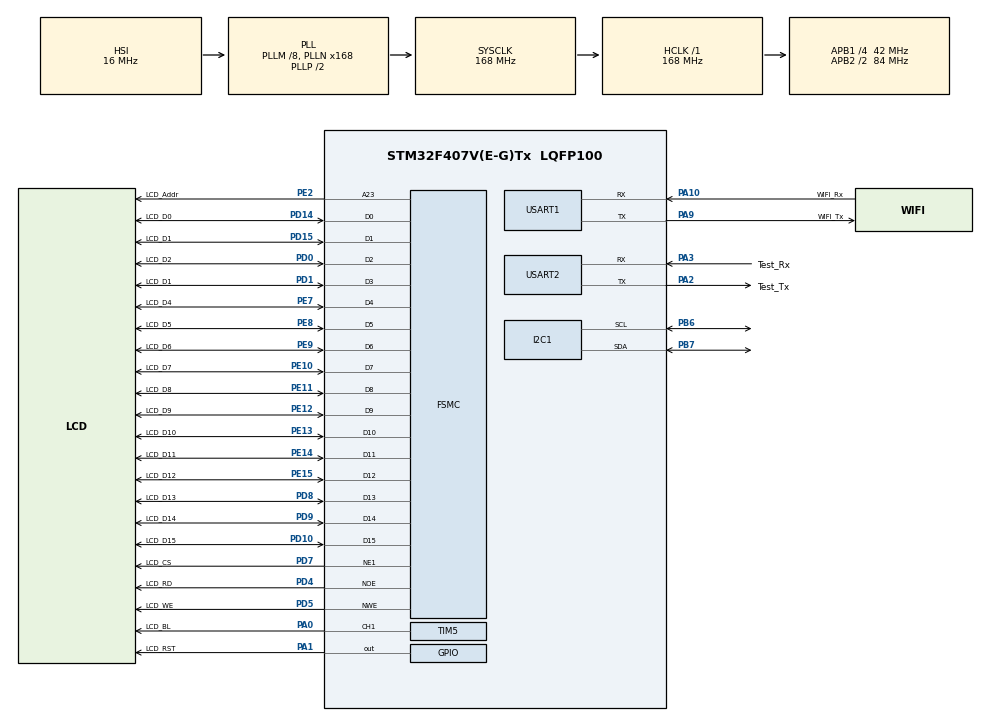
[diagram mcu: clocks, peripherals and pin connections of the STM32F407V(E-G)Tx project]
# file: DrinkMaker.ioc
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FREERTOS.Tasks01=defaultTask,24,128,StartDefaultTask,Default,NULL,Dynamic,NULL,NULL
FREERTOS.configTOTAL_HEAP_SIZE=30720
FSMC.AddressSetupTime1=3
FSMC.BusTurnAroundDuration1=0
FSMC.DataSetupTime1=40
FSMC.ExtendedAddressSetupTime1=0
FSMC.ExtendedDataSetupTime1=10
FSMC.ExtendedMode1=FSMC_EXTENDED_MODE_ENABLE
Mcu.Family=STM32F4
Mcu.Name=STM32F407V(E-G)Tx
Mcu.Package=LQFP100
NVIC.PriorityGroup=NVIC_PRIORITYGROUP_4
NVIC.TIM7_IRQn=true\:15\:0\:false\:false\:true\:false\:false\:true\:true
NVIC.TimeBase=TIM7_IRQn
NVIC.TimeBaseIP=TIM7
PA0-WKUP.GPIO_Label=LCD_BL
PA0-WKUP.GPIO_Speed=GPIO_SPEED_FREQ_VERY_HIGH
PA0-WKUP.Signal=S_TIM5_CH1
PA1.GPIO_Label=LCD_RST
PA1.GPIO_Speed=GPIO_SPEED_FREQ_HIGH
PA1.PinState=GPIO_PIN_SET
PA1.Signal=GPIO_Output
PA10.GPIO_Label=WIFI_Rx
PA10.Mode=Asynchronous
PA10.Signal=USART1_RX
PA2.GPIO_Label=Test_Tx
PA2.Mode=Asynchronous
PA2.Signal=USART2_TX
PA3.GPIO_Label=Test_Rx
PA3.Mode=Asynchronous
PA3.Signal=USART2_RX
PA9.GPIO_Label=WIFI_Tx
PA9.Mode=Asynchronous
PA9.Signal=USART1_TX
PB6.Mode=I2C
PB6.Signal=I2C1_SCL
PB7.Mode=I2C
PB7.Signal=I2C1_SDA
PC14-OSC32_IN.Mode=LSE-External-Oscillator
PC14-OSC32_IN.Signal=RCC_OSC32_IN
PC15-OSC32_OUT.Mode=LSE-External-Oscillator
PC15-OSC32_OUT.Signal=RCC_OSC32_OUT
PD0.GPIO_Label=LCD_D2
PD0.Mode=16b-d1
PD0.Signal=FSMC_D2
PD1.GPIO_Label=LCD_D1
PD1.Mode=16b-d1
PD1.Signal=FSMC_D3
PD10.GPIO_Label=LCD_D15
PD10.Mode=16b-d1
PD10.Signal=FSMC_D15
PD14.GPIO_Label=LCD_D0
PD14.Mode=16b-d1
PD14.Signal=FSMC_D0
PD15.GPIO_Label=LCD_D1
PD15.Mode=16b-d1
PD15.Signal=FSMC_D1
PD4.GPIO_Label=LCD_RD
PD4.Mode=Lcd1
PD4.Signal=FSMC_NOE
PD5.GPIO_Label=LCD_WE
PD5.Mode=Lcd1
PD5.Signal=FSMC_NWE
PD7.GPIO_Label=LCD_CS
PD7.Mode=NorPsramChipSelect1_1
PD7.Signal=FSMC_NE1
PD8.GPIO_Label=LCD_D13
PD8.Mode=16b-d1
PD8.Signal=FSMC_D13
PD9.GPIO_Label=LCD_D14
PD9.Mode=16b-d1
PD9.Signal=FSMC_D14
PE10.GPIO_Label=LCD_D7
PE10.Mode=16b-d1
PE10.Signal=FSMC_D7
PE11.GPIO_Label=LCD_D8
PE11.Mode=16b-d1
PE11.Signal=FSMC_D8
PE12.GPIO_Label=LCD_D9
PE12.Mode=16b-d1
PE12.Signal=FSMC_D9
PE13.GPIO_Label=LCD_D10
PE13.Mode=16b-d1
PE13.Signal=FSMC_D10
PE14.GPIO_Label=LCD_D11
PE14.Mode=16b-d1
PE14.Signal=FSMC_D11
PE15.GPIO_Label=LCD_D12
PE15.Mode=16b-d1
PE15.Signal=FSMC_D12
PE2.GPIO_Label=LCD_Addr
PE2.Mode=A23_1
PE2.Signal=FSMC_A23
PE7.GPIO_Label=LCD_D4
PE7.Mode=16b-d1
PE7.Signal=FSMC_D4
PE8.GPIO_Label=LCD_D5
PE8.Mode=16b-d1
PE8.Signal=FSMC_D5
PE9.GPIO_Label=LCD_D6
PE9.Mode=16b-d1
PE9.Signal=FSMC_D6
PH0-OSC_IN.Mode=HSE-External-Oscillator
PH0-OSC_IN.Signal=RCC_OSC_IN
PH1-OSC_OUT.Mode=HSE-External-Oscillator
PH1-OSC_OUT.Signal=RCC_OSC_OUT
ProjectManager.HeapSize=0x2000
ProjectManager.StackSize=0x4000
ProjectManager.TargetToolchain=MDK-ARM V5.32
RCC.48MHZClocksFreq_Value=84000000
RCC.AHBFreq_Value=168000000
RCC.APB1CLKDivider=RCC_HCLK_DIV4
RCC.APB1Freq_Value=42000000
RCC.APB1TimFreq_Value=84000000
RCC.APB2CLKDivider=RCC_HCLK_DIV2
RCC.APB2Freq_Value=84000000
RCC.APB2TimFreq_Value=168000000
RCC.CortexFreq_Value=168000000
RCC.HCLKFreq_Value=168000000
RCC.HSE_VALUE=25000000
RCC.HSI_VALUE=16000000
RCC.PLLM=8
RCC.PLLN=168
RCC.SYSCLKFreq_VALUE=168000000
RCC.SYSCLKSource=RCC_SYSCLKSOURCE_PLLCLK
RCC.VCOOutputFreq_Value=336000000
SH.S_TIM5_CH1.0=TIM5_CH1,PWM Generation1 CH1
TIM5.Channel-PWM\ Generation1\ CH1=TIM_CHANNEL_1
TIM5.Period=1000
TIM5.Prescaler=72
USART1.VirtualMode=VM_ASYNC
USART2.VirtualMode=VM_ASYNC
VP_FREERTOS_VS_CMSIS_V2.Mode=CMSIS_V2
VP_SYS_VS_tim7.Mode=TIM7
board=custom

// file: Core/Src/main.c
/* USER CODE BEGIN Header */
/**
  ******************************************************************************
  * @file           : main.c
  * @brief          : Main program body
  ******************************************************************************
  * @attention
  *
  * Copyright (c) 2025 STMicroelectronics.
  * All rights reserved.
  *
  * This software is licensed under terms that can be found in the LICENSE file
  * in the root directory of this software component.
  * If no LICENSE file comes with this software, it is provided AS-IS.
  *
  ******************************************************************************
  */
/* USER CODE END Header */
#include "main.h"
#include "cmsis_os.h"
#include "i2c.h"
#include "tim.h"
#include "usart.h"
#include "gpio.h"
#include "fsmc.h"

/* USER CODE BEGIN Includes */
#include "lvgl.h"
/* USER CODE END Includes */

void SystemClock_Config(void);
void MX_FREERTOS_Init(void);

int main(void)
{

  /* MCU Configuration--------------------------------------------------------*/

  /* Reset of all peripherals, Initializes the Flash interface and the Systick. */
  HAL_Init();

  /* Configure the system clock */
  SystemClock_Config();

  /* Initialize all configured peripherals */
  MX_GPIO_Init();
  MX_FSMC_Init();
  MX_I2C1_Init();
  MX_TIM5_Init();
  MX_USART1_UART_Init();
  MX_USART2_UART_Init();

  /* Init scheduler */
  osKernelInitialize();

  /* Call init function for freertos objects (in cmsis_os2.c) */
  MX_FREERTOS_Init();

  /* Start scheduler */
  osKernelStart();

  /* We should never get here as control is now taken by the scheduler */

  /* Infinite loop */
  while (1)
  {

  }
}

void SystemClock_Config(void)
{
  RCC_OscInitTypeDef RCC_OscInitStruct = {0};
  RCC_ClkInitTypeDef RCC_ClkInitStruct = {0};

  /** Configure the main internal regulator output voltage
  */
  __HAL_RCC_PWR_CLK_ENABLE();
  __HAL_PWR_VOLTAGESCALING_CONFIG(PWR_REGULATOR_VOLTAGE_SCALE1);

  /** Initializes the RCC Oscillators according to the specified parameters
  * in the RCC_OscInitTypeDef structure.
  */
  RCC_OscInitStruct.OscillatorType = RCC_OSCILLATORTYPE_HSI;
  RCC_OscInitStruct.HSIState = RCC_HSI_ON;
  RCC_OscInitStruct.HSICalibrationValue = RCC_HSICALIBRATION_DEFAULT;
  RCC_OscInitStruct.PLL.PLLState = RCC_PLL_ON;
  RCC_OscInitStruct.PLL.PLLSource = RCC_PLLSOURCE_HSI;
  RCC_OscInitStruct.PLL.PLLM = 8;
  RCC_OscInitStruct.PLL.PLLN = 168;
  RCC_OscInitStruct.PLL.PLLP = RCC_PLLP_DIV2;
  RCC_OscInitStruct.PLL.PLLQ = 4;
  if (HAL_RCC_OscConfig(&RCC_OscInitStruct) != HAL_OK)
  {
    Error_Handler();
  }

  /** Initializes the CPU, AHB and APB buses clocks
  */
  RCC_ClkInitStruct.ClockType = RCC_CLOCKTYPE_HCLK|RCC_CLOCKTYPE_SYSCLK
                              |RCC_CLOCKTYPE_PCLK1|RCC_CLOCKTYPE_PCLK2;
  RCC_ClkInitStruct.SYSCLKSource = RCC_SYSCLKSOURCE_PLLCLK;
  RCC_ClkInitStruct.AHBCLKDivider = RCC_SYSCLK_DIV1;
  RCC_ClkInitStruct.APB1CLKDivider = RCC_HCLK_DIV4;
  RCC_ClkInitStruct.APB2CLKDivider = RCC_HCLK_DIV2;

  if (HAL_RCC_ClockConfig(&RCC_ClkInitStruct, FLASH_LATENCY_5) != HAL_OK)
  {
    Error_Handler();
  }
}

void HAL_TIM_PeriodElapsedCallback(TIM_HandleTypeDef *htim)
{
  if (htim->Instance == TIM7)
  {
    HAL_IncTick();
  }
  /* USER CODE BEGIN Callback 1 */
  if (htim->Instance == TIM7)
  {
    lv_tick_inc(1);//设置lvgl心跳为1ms
  }
  /* USER CODE END Callback 1 */
}

void Error_Handler(void)
{
  __disable_irq();
  while (1)
  {
  }
}
